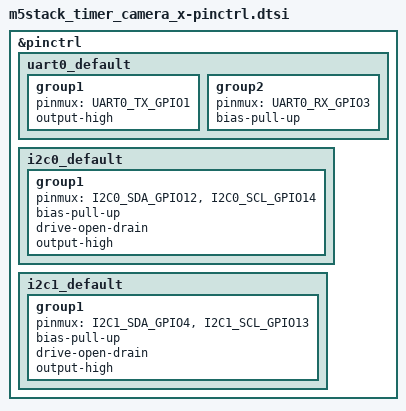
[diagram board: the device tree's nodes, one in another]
/*
 * Copyright The Zephyr Project Contributors
 *
 * SPDX-License-Identifier: Apache-2.0
 */

#include <zephyr/dt-bindings/pinctrl/esp32-pinctrl.h>

&pinctrl {
	uart0_default: uart0_default {
		group1 {
			pinmux = <UART0_TX_GPIO1>;
			output-high;
		};

		group2 {
			pinmux = <UART0_RX_GPIO3>;
			bias-pull-up;
		};
	};

	/* The board has no pull-ups on the RTC bus */
	i2c0_default: i2c0_default {
		group1 {
			pinmux = <I2C0_SDA_GPIO12>,
				 <I2C0_SCL_GPIO14>;
			bias-pull-up;
			drive-open-drain;
			output-high;
		};
	};

	i2c1_default: i2c1_default {
		group1 {
			pinmux = <I2C1_SDA_GPIO4>,
				 <I2C1_SCL_GPIO13>;
			bias-pull-up;
			drive-open-drain;
			output-high;
		};
	};
};
